AUTOSAR XML (schema 314)
package /ComponentType
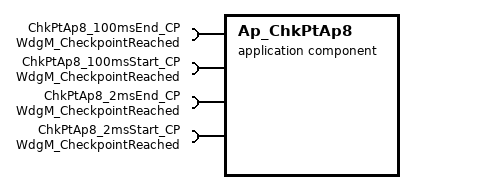
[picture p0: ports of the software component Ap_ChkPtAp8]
  application software component type Ap_ChkPtAp8
    4 x require port, all with client-com-spec=CheckpointReached, required-interface=WdgM_CheckpointReached:
      ChkPtAp8_100msEnd_CP
      ChkPtAp8_100msStart_CP
      ChkPtAp8_2msEnd_CP
      ChkPtAp8_2msStart_CP
  internal behavior Ap_ChkPtAp8_InternalBehavior: component=Ap_ChkPtAp8
    4 x timing event:
      TMT_ChkPtAp8_100msEnd_Per: start-on-event=ChkPtAp8_100msEnd_Per, period=0.1
      TMT_ChkPtAp8_100msStart_Per: start-on-event=ChkPtAp8_100msStart_Per, period=0.1
      TMT_ChkPtAp8_2msEnd_Per: start-on-event=ChkPtAp8_2msEnd_Per, period=0.002
      TMT_ChkPtAp8_2msStart_Per: start-on-event=ChkPtAp8_2msStart_Per, period=0.002
    port-api-options:
      enable-take-address=false, indirect-api=false, port=ChkPtAp8_100msEnd_CP
      enable-take-address=false, indirect-api=false, port=ChkPtAp8_100msStart_CP
      enable-take-address=false, indirect-api=false, port=ChkPtAp8_2msEnd_CP
      enable-take-address=false, indirect-api=false, port=ChkPtAp8_2msStart_CP
    4 x runnable:
      ChkPtAp8_100msEnd_Per
        sync call SC_ChkPtAp8_100msEnd_CP_CheckpointReached: operation=ChkPtAp8_100msEnd_CP.CheckpointReached, timeout=0
      ChkPtAp8_100msStart_Per
        sync call SC_ChkPtAp8_100msStart_CP_CheckpointReached: operation=ChkPtAp8_100msStart_CP.CheckpointReached, timeout=0
      ChkPtAp8_2msEnd_Per
        sync call SC_ChkPtAp8_2msEnd_CP_CheckpointReached: operation=ChkPtAp8_2msEnd_CP.CheckpointReached, timeout=0
      ChkPtAp8_2msStart_Per
        sync call SC_ChkPtAp8_2msStart_CP_CheckpointReached: operation=ChkPtAp8_2msStart_CP.CheckpointReached, timeout=0
  swc implementation Ap_ChkPtAp8_Implementation: behavior=Ap_ChkPtAp8_InternalBehavior
    code-descriptors:
      code Code: type=SRC
